# ASR6601 register map
Vendor: ASR Microelectronics; Series: ASR6601; File version: 1
CPU: CM4 r0p1, little endian, no MPU, FPU, 3 interrupt priority bits
Registers are 32-bit, read-write, reset 0x0 unless marked. A register's access mark holds for its fields unless they carry their own. Offsets are from the block's base; [hi:lo] are bit positions; {n}, {i} and the like mark numbered series; 'fields as' and 'values as' point back to an identical list.

## SSP0 — Synchronous Serial Port Controller
Base 0x40006000
Same registers: SSP1 0x40012000, SSP2 0x40013000
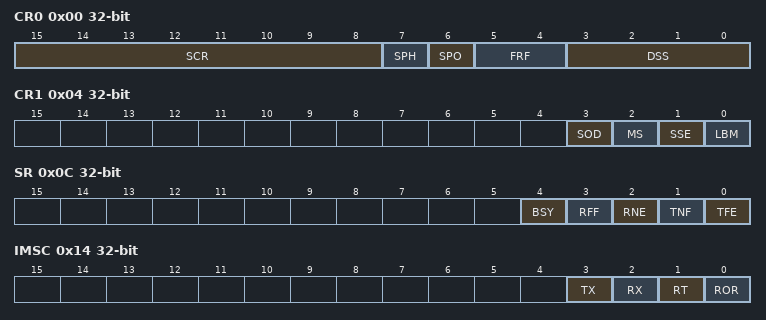
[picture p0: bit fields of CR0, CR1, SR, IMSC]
0x00 CR0 — Control register 0
  [15:8] SCR — Serial clock rate
  [7] SPH — Serial clock phase
    0=1EDGE (Data is captured on the first clock edge transition); 1=2EDGE (Data is captured on the second clock edge transition)
  [6] SPO — Serial clock polarity
    0=LOW (A steady state LOW value on the clock pin); 1=HIGH (A steady state HIGH value on the clock pin)
  [5:4] FRF — Frame format
    0=SPI (Motorola SPI frame format); 1=TI (TI synchronous serial frame format); 2=MW (National Microwire frame format)
  [3:0] DSS — Data size select
    {v}={v+1}BIT ({v+1}-bit data) (v=3..15)
0x04 CR1 — Control register 1
  [3] SOD — Slave-mode output disable
    0=EN (SSP can drive the TXD output in slave mode); 1=DIS (SSP must not drive the TXD output in slave mode)
  [2] MS — Master or slave mode select
    0=MASTER (Device configured as master); 1=SLAVE (Device configured as slave)
  [1] SSE — SSP enable
    0=DIS (SSP disable); 1=EN (SSP enable)
  [0] LBM — Loop back mode
    0=DIS (Normal serial port operation enabled); 1=EN (Output of transmit serial shifter is connected to input of receive serial shifter internally)
0x08 DR — Data register
0x0C SR ro — Status register
  [4] BSY — SSP busy flag
    0=CLR_FLAG (SSP is idle); 1=SET_FLAG (SSP is currently transmitting and/or receiving a frame or the transmit FIFO is not empty)
  [3] RFF — Receive FIFO full
    0=CLR_FLAG (Receive FIFO is not full); 1=SET_FLAG (Receive FIFO is full)
  [2] RNE — Receive FIFO not empty
    0=CLR_FLAG (Receive FIFO is empty); 1=SET_FLAG (Receive FIFO is not empty)
  [1] TNF — Transmit FIFO not full
    0=CLR_FLAG (Transmit FIFO is full); 1=SET_FLAG (Transmit FIFO is not full)
  [0] TFE — Transmit FIFO empty
    0=CLR_FLAG (Transmit FIFO is not empty); 1=SET_FLAG (Transmit FIFO is empty)
0x10 CPSR — Clock prescale register
  [7:0] CPSDVSR — Clock prescale divisor. Must be an even number between 2-254
0x14 IMSC — Interrupt mask set or clear register
  [3] TX — Transmit FIFO interrupt mask
    0=CLR_FLAG (Transmit FIFO half empty or less condition interrupt is masked); 1=SET_FLAG (Transmit FIFO half empty or less condition interrupt is not masked)
  [2] RX — Receive FIFO interrupt mask
    0=CLR_FLAG (Receive FIFO half full or less condition interrupt is masked); 1=SET_FLAG (Receive FIFO half full or less condition interrupt is not masked)
  [1] RT — Receive timeout interrupt mask
    0=CLR_FLAG (Receive FIFO not empty and no read prior to timeout period interrupt is masked); 1=SET_FLAG (Receive FIFO not empty and no read prior to timeout period interrupt is not masked)
  [0] ROR — Receive overrun interrupt mask
    0=CLR_FLAG (Receive FIFO written to while full condition interrupt is masked); 1=SET_FLAG (Receive FIFO written to while full condition interrupt is not masked)
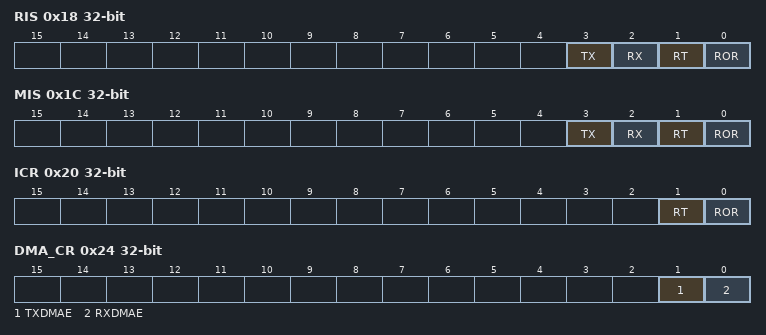
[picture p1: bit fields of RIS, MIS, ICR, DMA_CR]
0x18 RIS ro — Raw interrupt status register
  [3] TX — Transmit FIFO interrupt status
    0=CLR_FLAG (Interrupt not triggered: Transmit FIFO half empty or less); 1=SET_FLAG (Interrupt triggered: Transmit FIFO half empty or less)
  [2] RX — Receive FIFO interrupt status
    0=CLR_FLAG (Interrupt not triggered: Receive FIFO half full or less); 1=SET_FLAG (Interrupt triggered: Receive FIFO half full or less)
  [1] RT — Receive timeout interrupt status
    0=CLR_FLAG (Interrupt not triggered: Receive FIFO not empty and no read prior to timeout period); 1=SET_FLAG (Interrupt triggered: Receive FIFO not empty and no read prior to timeout period)
  [0] ROR — Receive overrun interrupt status
    0=CLR_FLAG (Interrupt not triggered: Receive FIFO written to while full condition); 1=SET_FLAG (Interrupt triggered: Receive FIFO written to while full condition)
0x1C MIS ro — Masked interrupt status register
  [3] TX — Transmit FIFO masked interrupt status
    values as RIS.TX
  [2] RX — Receive FIFO masked interrupt status
    values as RIS.RX
  [1] RT — Receive timeout masked interrupt status
    values as RIS.RT
  [0] ROR — Receive overrun masked interrupt status
    values as RIS.ROR
0x20 ICR wo — Interrupt clear register
  [1] RT — Receive timeout interrupt clear
    0=CLR_FLAG (No effect); 1=SET_FLAG (Clear interrupt: Receive FIFO not empty and no read prior to timeout period)
  [0] ROR — Receive overrun interrupt clear
    0=CLR_FLAG (No effect); 1=SET_FLAG (Clear interrupt: Receive FIFO written to while full condition)
0x24 DMA_CR — DMA control register
  [1] TXDMAE — Transmit DMA enable
    0=DIS (Transmit DMA disable); 1=EN (Transmit DMA enable)
  [0] RXDMAE — Receive DMA enable
    0=DIS (Receive DMA disable); 1=EN (Receive DMA enable)

## EFC — Embedded Flash Controller
Base 0x40020000
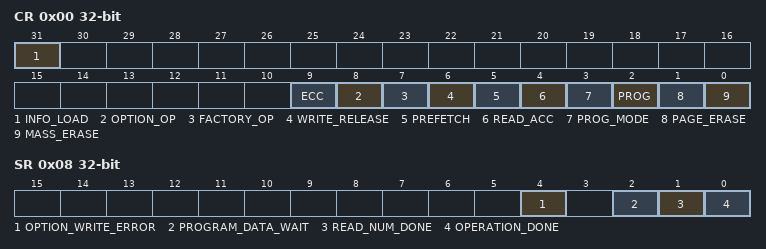
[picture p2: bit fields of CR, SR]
0x00 CR — Control register
  [31] INFO_LOAD
    0=DIS (UNKNOWN); 1=EN (UNKNOWN)
  [9] ECC — Error correction code
    0=DIS (ECC disable); 1=EN (ECC enable)
  [8] OPTION_OP
    0=DIS (UNKNOWN); 1=EN (UNKNOWN)
  [7] FACTORY_OP
    0=DIS (UNKNOWN); 1=EN (UNKNOWN)
  [6] WRITE_RELEASE
    0=DIS (UNKNOWN); 1=EN (UNKNOWN)
  [5] PREFETCH — Prefetch buffer
    0=DIS (Prefetch buffer disable); 1=EN (Prefetch buffer enable)
  [4] READ_ACC
    0=DIS (UNKNOWN); 1=EN (UNKNOWN)
  [3] PROG_MODE — Flash programming mode
    0=DWORD (4 bytes); 1=WLINE (512 bytes)
  [2] PROG — Flash programming
    0=DIS (Flash programming disable); 1=EN (Flash programming enable)
  [1] PAGE_ERASE
    0=DIS (Page erase disable); 1=EN (Page erase enable)
  [0] MASS_ERASE
    0=DIS (Mass erase disable); 1=EN (Mass erase enable)
0x04 INT_EN — Interrupt enable register
0x08 SR — Status register
  [4] OPTION_WRITE_ERROR
    0=CLR_FLAG (UNKNOWN); 1=SET_FLAG (UNKNOWN)
  [2] PROGRAM_DATA_WAIT — Wait for data programming
    0=CLR_FLAG (Wait); 1=SET_FLAG (Don't wait)
  [1] READ_NUM_DONE — Latency? change
    0=CLR_FLAG (Latency? change in progress); 1=SET_FLAG (Latency? change done)
  [0] OPERATION_DONE — Operation
    0=CLR_FLAG (Operation in progress); 1=SET_FLAG (Operation done)
0x0C PROGRAM_DATA0
0x10 PROGRAM_DATA1
0x14 TIMING_CFG — Timing config register
  [19:16] READ_NUM — Latency?
0x18 PROTECT_SEQ wo — Security sequence
0x20 CHIP_PATTERN ro
0x24 IP_TRIM_L ro — Analog ip trimming low register
0x28 IP_TRIM_H ro — Analog ip trimming high register
0x2C SN_L ro — Serial number low register
0x30 SN_H ro — Serial number high register
0x34 TEST_INFO_L ro — Test info low register
0x38 TEST_INFO_H ro — Test info high register
0x3C OPTION_CSR_BYTES ro — Option control and status register
0x40 OPTION_EO_BYTES ro — Option exe-only bytes register
0x44 OPTION_WP_BYTES ro — Option write-protect bytes register
0x48 OPTION_SEC_BYTES0 ro — Option secure byte 0 register
0x4C OPTION_SEC_BYTES1 ro — Option secure byte 1 register

## GPIOA — General-purpose I/Os
Base 0x4001F000
Same registers: GPIOB 0x4001F400, GPIOC 0x4001F800, GPIOD 0x4001FC00
0x00 OER reset 0xFFFF — Output enable register
0x04 OTYPER — Output type register
0x08 IER — Input type register
0x0C PER — Pull enable register
0x10 PSR — Pull select register
0x14 IDR ro — Input data register
0x18 ODR — Output data register
0x1C BRR wo — Bit reset register
0x20 BSR wo — Bit set register
0x24 DSR — Drive set register
0x28 ICR — Interrupt control register
0x2C IFR — Interrupt flag register
0x30 WUCR — Wakeup control register
0x34 WULVL — Wakeup level register
0x38 AFRL — Alternate function low register
0x3C AFRH — Alternate function high register
0x40 STOP3_WUCR — Stop3 wakeup control register
